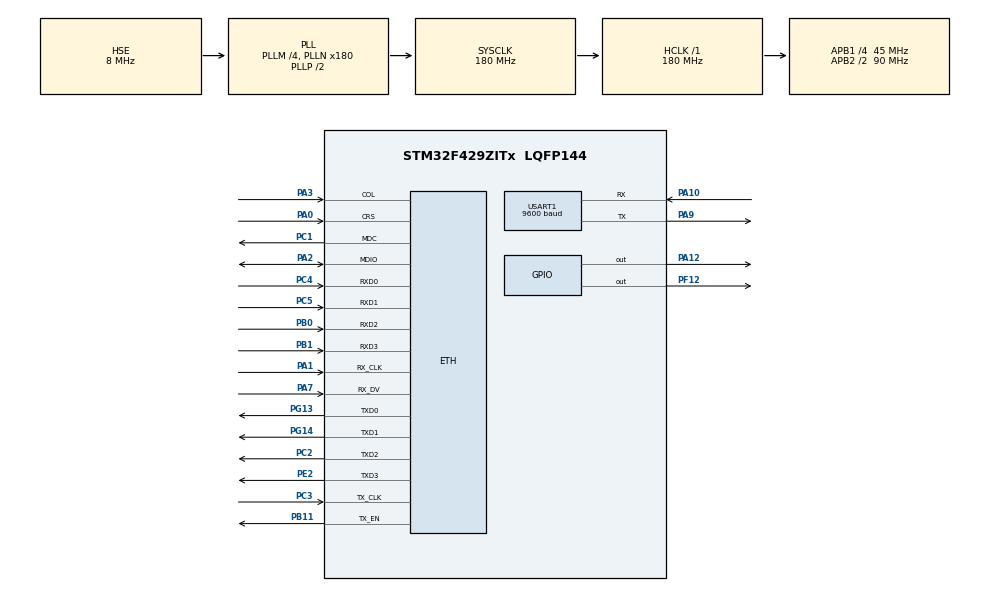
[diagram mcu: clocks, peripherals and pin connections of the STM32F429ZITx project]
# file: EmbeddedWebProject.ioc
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Dma.Request0=USART1_TX
Dma.Request1=USART1_RX
Dma.USART1_RX.1.Direction=DMA_PERIPH_TO_MEMORY
Dma.USART1_RX.1.FIFOMode=DMA_FIFOMODE_DISABLE
Dma.USART1_RX.1.Instance=DMA2_Stream2
Dma.USART1_RX.1.MemDataAlignment=DMA_MDATAALIGN_BYTE
Dma.USART1_RX.1.MemInc=DMA_MINC_ENABLE
Dma.USART1_RX.1.Mode=DMA_NORMAL
Dma.USART1_RX.1.PeriphDataAlignment=DMA_PDATAALIGN_BYTE
Dma.USART1_RX.1.PeriphInc=DMA_PINC_DISABLE
Dma.USART1_RX.1.Priority=DMA_PRIORITY_LOW
Dma.USART1_TX.0.Direction=DMA_MEMORY_TO_PERIPH
Dma.USART1_TX.0.FIFOMode=DMA_FIFOMODE_DISABLE
Dma.USART1_TX.0.Instance=DMA2_Stream7
Dma.USART1_TX.0.MemDataAlignment=DMA_MDATAALIGN_BYTE
Dma.USART1_TX.0.MemInc=DMA_MINC_ENABLE
Dma.USART1_TX.0.Mode=DMA_NORMAL
Dma.USART1_TX.0.PeriphDataAlignment=DMA_PDATAALIGN_BYTE
Dma.USART1_TX.0.PeriphInc=DMA_PINC_DISABLE
Dma.USART1_TX.0.Priority=DMA_PRIORITY_LOW
ETH.MediaInterface=HAL_ETH_MII_MODE
FREERTOS.Tasks01=defaultTask,24,128,StartDefaultTask,Default,NULL,Dynamic,NULL,NULL
LWIP.BSP.number=1
LWIP.Version=v2.1.2_Cube
LWIP0.BSP.STBoard=false
LWIP0.BSP.api=BSP_COMPONENT_DRIVER
LWIP0.BSP.component=DP83848
LWIP0.BSP.instance=DP83848
LWIP0.BSP.name=Driver_PHY
LWIP0.BSP.semaphore=S_DP83848
LWIP0.BSP.solution=DP83848
Mcu.Family=STM32F4
Mcu.Name=STM32F429ZITx
Mcu.Package=LQFP144
NVIC.DMA2_Stream2_IRQn=true\:5\:0\:false\:false\:true\:true\:false\:true\:true
NVIC.DMA2_Stream7_IRQn=true\:5\:0\:false\:false\:true\:true\:false\:true\:true
NVIC.ETH_IRQn=true\:5\:0\:false\:false\:true\:true\:true\:true\:true
NVIC.PriorityGroup=NVIC_PRIORITYGROUP_4
PA0/WKUP.Mode=MII
PA0/WKUP.Signal=ETH_CRS
PA1.Mode=MII
PA1.Signal=ETH_RX_CLK
PA10.Mode=Asynchronous
PA10.Signal=USART1_RX
PA12.Signal=GPIO_Output
PA13.Mode=Serial_Wire
PA13.Signal=SYS_JTMS-SWDIO
PA14.Mode=Serial_Wire
PA14.Signal=SYS_JTCK-SWCLK
PA2.Mode=MII
PA2.Signal=ETH_MDIO
PA3.Mode=MII
PA3.Signal=ETH_COL
PA7.Mode=MII
PA7.Signal=ETH_RX_DV
PA9.Mode=Asynchronous
PA9.Signal=USART1_TX
PB0.Mode=MII
PB0.Signal=ETH_RXD2
PB1.Mode=MII
PB1.Signal=ETH_RXD3
PB11.Mode=MII
PB11.Signal=ETH_TX_EN
PC1.Mode=MII
PC1.Signal=ETH_MDC
PC2.Mode=MII
PC2.Signal=ETH_TXD2
PC3.Mode=MII
PC3.Signal=ETH_TX_CLK
PC4.Mode=MII
PC4.Signal=ETH_RXD0
PC5.Mode=MII
PC5.Signal=ETH_RXD1
PE2.Mode=MII
PE2.Signal=ETH_TXD3
PF12.Signal=GPIO_Output
PG13.Mode=MII
PG13.Signal=ETH_TXD0
PG14.Mode=MII
PG14.Signal=ETH_TXD1
PH0/OSC_IN.Mode=HSE-External-Oscillator
PH0/OSC_IN.Signal=RCC_OSC_IN
PH1/OSC_OUT.Mode=HSE-External-Oscillator
PH1/OSC_OUT.Signal=RCC_OSC_OUT
ProjectManager.HeapSize=0x200
ProjectManager.StackSize=0x400
ProjectManager.TargetToolchain=STM32CubeIDE
RCC.48MHZClocksFreq_Value=90000000
RCC.AHBFreq_Value=180000000
RCC.APB1CLKDivider=RCC_HCLK_DIV4
RCC.APB1Freq_Value=45000000
RCC.APB1TimFreq_Value=90000000
RCC.APB2CLKDivider=RCC_HCLK_DIV2
RCC.APB2Freq_Value=90000000
RCC.APB2TimFreq_Value=180000000
RCC.CortexFreq_Value=180000000
RCC.HCLKFreq_Value=180000000
RCC.HSE_VALUE=8000000
RCC.HSI_VALUE=16000000
RCC.LSE_VALUE=32768
RCC.PLLM=4
RCC.PLLN=180
RCC.PLLSourceVirtual=RCC_PLLSOURCE_HSE
RCC.SYSCLKFreq_VALUE=180000000
RCC.SYSCLKSource=RCC_SYSCLKSOURCE_PLLCLK
RCC.VCOOutputFreq_Value=360000000
USART1.BaudRate=9600
USART1.VirtualMode=VM_ASYNC
VP_FREERTOS_VS_CMSIS_V2.Mode=CMSIS_V2
VP_LWIP_VS_Enabled.Mode=Enabled
board=custom

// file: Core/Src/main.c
/* USER CODE BEGIN Header */
/**
  ******************************************************************************
  * @file           : main.c
  * @brief          : Main program body
  ******************************************************************************
  * @attention
  *
  * Copyright (c) 2026 STMicroelectronics.
  * All rights reserved.
  *
  * This software is licensed under terms that can be found in the LICENSE file
  * in the root directory of this software component.
  * If no LICENSE file comes with this software, it is provided AS-IS.
  * LastGoRun
  *
  ******************************************************************************
  */
/* USER CODE END Header */
#include "main.h"
#include "cmsis_os.h"
#include "lwip.h"
#include "httpserver-netconn.h"
#include "app_config.h"
#include "modbus_rtu_master.h"
#include "network_config.h"
#include "rs485_interface.h"
#include "polling_engine.h"

/* USER CODE BEGIN Includes ahmed naciri was here*/

/* USER CODE END Includes */

UART_HandleTypeDef huart1;
DMA_HandleTypeDef hdma_usart1_tx;
DMA_HandleTypeDef hdma_usart1_rx;

/* Definitions for defaultTask */
osThreadId_t defaultTaskHandle;
const osThreadAttr_t defaultTask_attributes = {
  .name = "defaultTask",
  .stack_size = 1024 * 4,
  .priority = (osPriority_t) osPriorityNormal,
};

void SystemClock_Config(void);
static void MX_GPIO_Init(void);
static void MX_DMA_Init(void);
static void MX_USART1_UART_Init(void);
void StartDefaultTask(void *argument);

/* USER CODE BEGIN 0 */
void HAL_UART_RxCpltCallback(UART_HandleTypeDef *huart)
{
	 modbusMaster_cpltCallBack(huart);

}

/* USER CODE END 0 */

int main(void)
{

  /* MCU Configuration--------------------------------------------------------*/

  /* Reset of all peripherals, Initializes the Flash interface and the Systick. */
  HAL_Init();

  /* Configure the system clock */
  SystemClock_Config();

  /* Initialize all configured peripherals */
  MX_GPIO_Init();
  MX_DMA_Init();
  MX_USART1_UART_Init();
  /* USER CODE BEGIN 2 */
  rs485_interface_init();
  modbusMaster_init();
  //uint8_t testFrame[8] = {0x01,0x03,0x00,0x00,0x00,0x01,0x84,0x0A};

  /* USER CODE END 2 */

  /* Init scheduler */
  osKernelInitialize();

  /* Create the thread(s) */
  /* creation of defaultTask */
  defaultTaskHandle = osThreadNew(StartDefaultTask, NULL, &defaultTask_attributes);

  /* Start scheduler */
  osKernelStart();

  /* We should never get here as control is now taken by the scheduler */

  /* Infinite loop */
  /* USER CODE BEGIN WHILE */
  while (1)
  {
//	      HAL_GPIO_WritePin(GPIOD, GPIO_PIN_12, GPIO_PIN_SET);
//
//	      HAL_UART_Transmit(&huart1, testFrame, 8, 1000);
//
//	      HAL_GPIO_WritePin(GPIOD, GPIO_PIN_12, GPIO_PIN_RESET);
//
//	      HAL_Delay(1000);

    /* USER CODE END WHILE */

  }
}

void SystemClock_Config(void)
{
  RCC_OscInitTypeDef RCC_OscInitStruct = {0};
  RCC_ClkInitTypeDef RCC_ClkInitStruct = {0};

  /** Configure the main internal regulator output voltage
  */
  __HAL_RCC_PWR_CLK_ENABLE();
  __HAL_PWR_VOLTAGESCALING_CONFIG(PWR_REGULATOR_VOLTAGE_SCALE1);

  /** Initializes the RCC Oscillators according to the specified parameters
  * in the RCC_OscInitTypeDef structure.
  */
  RCC_OscInitStruct.OscillatorType = RCC_OSCILLATORTYPE_HSE;
  RCC_OscInitStruct.HSEState = RCC_HSE_ON;
  RCC_OscInitStruct.PLL.PLLState = RCC_PLL_ON;
  RCC_OscInitStruct.PLL.PLLSource = RCC_PLLSOURCE_HSE;
  RCC_OscInitStruct.PLL.PLLM = 4;
  RCC_OscInitStruct.PLL.PLLN = 180;
  RCC_OscInitStruct.PLL.PLLP = RCC_PLLP_DIV2;
  RCC_OscInitStruct.PLL.PLLQ = 4;
  if (HAL_RCC_OscConfig(&RCC_OscInitStruct) != HAL_OK)
  {
    Error_Handler();
  }

  /** Activate the Over-Drive mode
  */
  if (HAL_PWREx_EnableOverDrive() != HAL_OK)
  {
    Error_Handler();
  }

  /** Initializes the CPU, AHB and APB buses clocks
  */
  RCC_ClkInitStruct.ClockType = RCC_CLOCKTYPE_HCLK|RCC_CLOCKTYPE_SYSCLK
                              |RCC_CLOCKTYPE_PCLK1|RCC_CLOCKTYPE_PCLK2;
  RCC_ClkInitStruct.SYSCLKSource = RCC_SYSCLKSOURCE_PLLCLK;
  RCC_ClkInitStruct.AHBCLKDivider = RCC_SYSCLK_DIV1;
  RCC_ClkInitStruct.APB1CLKDivider = RCC_HCLK_DIV4;
  RCC_ClkInitStruct.APB2CLKDivider = RCC_HCLK_DIV2;

  if (HAL_RCC_ClockConfig(&RCC_ClkInitStruct, FLASH_LATENCY_5) != HAL_OK)
  {
    Error_Handler();
  }
}

static void MX_USART1_UART_Init(void)
{

  huart1.Instance = USART1;
  huart1.Init.BaudRate = 9600;
  huart1.Init.WordLength = UART_WORDLENGTH_8B;
  huart1.Init.StopBits = UART_STOPBITS_1;
  huart1.Init.Parity = UART_PARITY_NONE;
  huart1.Init.Mode = UART_MODE_TX_RX;
  huart1.Init.HwFlowCtl = UART_HWCONTROL_NONE;
  huart1.Init.OverSampling = UART_OVERSAMPLING_16;
  if (HAL_UART_Init(&huart1) != HAL_OK)
  {
    Error_Handler();
  }

}

static void MX_DMA_Init(void)
{

  /* DMA controller clock enable */
  __HAL_RCC_DMA2_CLK_ENABLE();

  /* DMA interrupt init */
  /* DMA2_Stream2_IRQn interrupt configuration */
  HAL_NVIC_SetPriority(DMA2_Stream2_IRQn, 5, 0);
  HAL_NVIC_EnableIRQ(DMA2_Stream2_IRQn);
  /* DMA2_Stream7_IRQn interrupt configuration */
  HAL_NVIC_SetPriority(DMA2_Stream7_IRQn, 5, 0);
  HAL_NVIC_EnableIRQ(DMA2_Stream7_IRQn);

}

static void MX_GPIO_Init(void)
{
  GPIO_InitTypeDef GPIO_InitStruct = {0};

  /* GPIO Ports Clock Enable */
  __HAL_RCC_GPIOE_CLK_ENABLE();
  __HAL_RCC_GPIOH_CLK_ENABLE();
  __HAL_RCC_GPIOC_CLK_ENABLE();
  __HAL_RCC_GPIOA_CLK_ENABLE();
  __HAL_RCC_GPIOB_CLK_ENABLE();
  __HAL_RCC_GPIOF_CLK_ENABLE();
  __HAL_RCC_GPIOG_CLK_ENABLE();

  /*Configure GPIO pin Output Level */
  HAL_GPIO_WritePin(GPIOF, GPIO_PIN_12, GPIO_PIN_RESET);

  /*Configure GPIO pin Output Level */
  HAL_GPIO_WritePin(GPIOA, GPIO_PIN_12, GPIO_PIN_RESET);

  /*Configure GPIO pin : PF12 */
  GPIO_InitStruct.Pin = GPIO_PIN_12;
  GPIO_InitStruct.Mode = GPIO_MODE_OUTPUT_PP;
  GPIO_InitStruct.Pull = GPIO_NOPULL;
  GPIO_InitStruct.Speed = GPIO_SPEED_FREQ_LOW;
  HAL_GPIO_Init(GPIOF, &GPIO_InitStruct);

  /*Configure GPIO pin : PA12 */
  GPIO_InitStruct.Pin = GPIO_PIN_12;
  GPIO_InitStruct.Mode = GPIO_MODE_OUTPUT_PP;
  GPIO_InitStruct.Pull = GPIO_NOPULL;
  GPIO_InitStruct.Speed = GPIO_SPEED_FREQ_LOW;
  HAL_GPIO_Init(GPIOA, &GPIO_InitStruct);

}

void StartDefaultTask(void *argument)
{
  /* 1) Load persisted network configuration from EEPROM emulation.
     This must happen before lwIP init so boot uses saved IP settings. */
  network_config_load();
    /* Load persisted Modbus app configuration before runtime tasks use appDb. */
    appConfig_load();
  /* init code for LWIP */
  /* 2) Apply loaded IP/netmask/gateway and bring lwIP/netif up. */
  MX_LWIP_Init();// Now we have a properly configured Ethernet interface
  /* 3) Start the HTTP server thread after networking is initialized. */
  http_server_netconn_init();//The server uses the Netconn API of LwIP.
  /* USER CODE BEGIN 5 */
  /* 4) Initialize polling engine for Modbus master periodic task */
  pollingEngine_init();
  /* Infinite loop */
  for(;;)
  {
    /* Run Modbus slave polling loop (iterate slaves/registers and issue reads) */
    pollingEngine_task();
    osDelay(1);
  }
  /* USER CODE END 5 */
}

void Error_Handler(void)
{
  __disable_irq();
  while (1)
  {
  }
}
